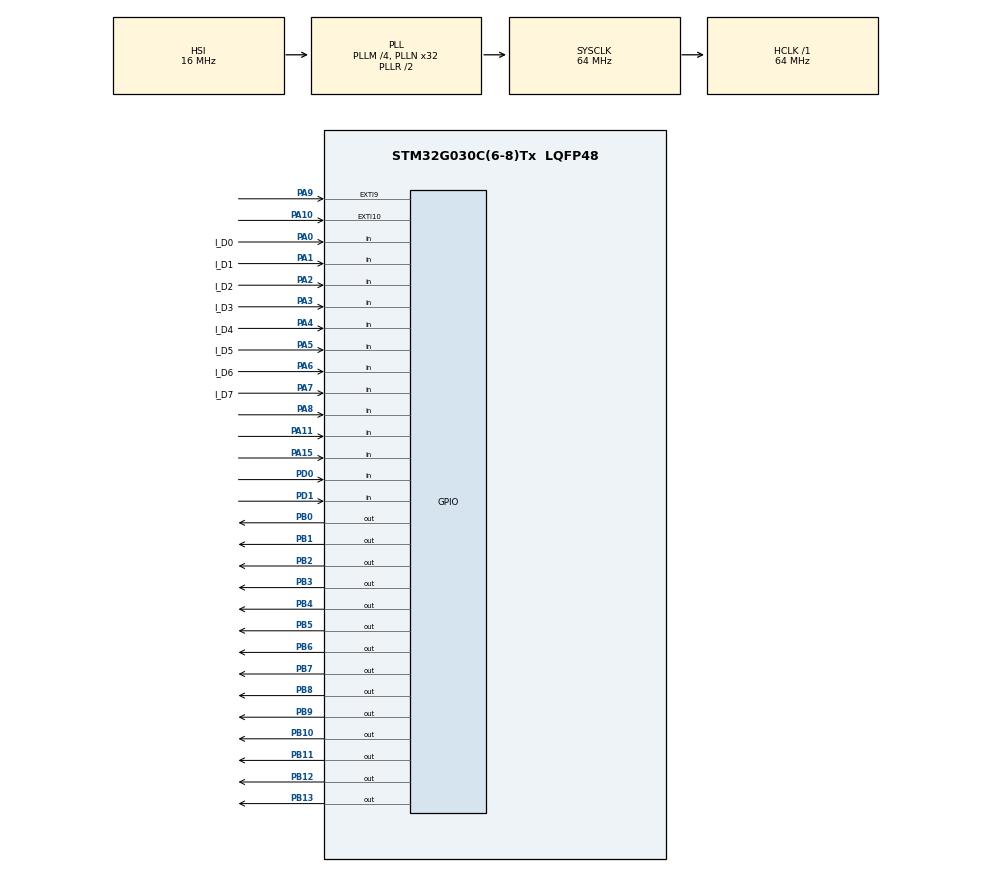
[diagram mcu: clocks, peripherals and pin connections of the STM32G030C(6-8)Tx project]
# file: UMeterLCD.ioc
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Mcu.Family=STM32G0
Mcu.Name=STM32G030C(6-8)Tx
Mcu.Package=LQFP48
NVIC.EXTI4_15_IRQn=true\:0\:0\:false\:false\:true\:true\:true\:true
PA0.GPIO_Label=I_D0
PA0.GPIO_PuPd=GPIO_NOPULL
PA0.Signal=GPIO_Input
PA1.GPIO_Label=I_D1
PA1.GPIO_PuPd=GPIO_NOPULL
PA1.Signal=GPIO_Input
PA10.GPIO_ModeDefaultEXTI=GPIO_MODE_IT_RISING
PA10.GPIO_PuPd=GPIO_NOPULL
PA10.Signal=GPXTI10
PA11\ [PA9].GPIO_PuPd=GPIO_NOPULL
PA11\ [PA9].Signal=GPIO_Input
PA15.GPIO_PuPd=GPIO_PULLUP
PA15.Signal=GPIO_Input
PA2.GPIO_Label=I_D2
PA2.GPIO_PuPd=GPIO_NOPULL
PA2.Signal=GPIO_Input
PA3.GPIO_Label=I_D3
PA3.GPIO_PuPd=GPIO_NOPULL
PA3.Signal=GPIO_Input
PA4.GPIO_Label=I_D4
PA4.GPIO_PuPd=GPIO_NOPULL
PA4.Signal=GPIO_Input
PA5.GPIO_Label=I_D5
PA5.GPIO_PuPd=GPIO_NOPULL
PA5.Signal=GPIO_Input
PA6.GPIO_Label=I_D6
PA6.GPIO_PuPd=GPIO_NOPULL
PA6.Signal=GPIO_Input
PA7.GPIO_Label=I_D7
PA7.GPIO_PuPd=GPIO_NOPULL
PA7.Signal=GPIO_Input
PA8.Signal=GPIO_Input
PA9.GPIO_ModeDefaultEXTI=GPIO_MODE_IT_FALLING
PA9.Signal=GPXTI9
PB0.GPIO_ModeDefaultOutputPP=GPIO_MODE_OUTPUT_PP
PB0.GPIO_PuPd=GPIO_NOPULL
PB0.GPIO_Speed=GPIO_SPEED_FREQ_VERY_HIGH
PB0.Signal=GPIO_Output
PB1.GPIO_PuPd=GPIO_NOPULL
PB1.GPIO_Speed=GPIO_SPEED_FREQ_VERY_HIGH
PB1.Signal=GPIO_Output
PB10.GPIO_PuPd=GPIO_NOPULL
PB10.GPIO_Speed=GPIO_SPEED_FREQ_VERY_HIGH
PB10.PinState=GPIO_PIN_SET
PB10.Signal=GPIO_Output
PB11.GPIO_PuPd=GPIO_NOPULL
PB11.GPIO_Speed=GPIO_SPEED_FREQ_VERY_HIGH
PB11.Signal=GPIO_Output
PB12.GPIO_PuPd=GPIO_NOPULL
PB12.GPIO_Speed=GPIO_SPEED_FREQ_VERY_HIGH
PB12.Signal=GPIO_Output
PB13.PinState=GPIO_PIN_SET
PB13.Signal=GPIO_Output
PB2.GPIO_PuPd=GPIO_NOPULL
PB2.GPIO_Speed=GPIO_SPEED_FREQ_VERY_HIGH
PB2.Signal=GPIO_Output
PB3.GPIO_PuPd=GPIO_NOPULL
PB3.GPIO_Speed=GPIO_SPEED_FREQ_VERY_HIGH
PB3.Signal=GPIO_Output
PB4.GPIO_PuPd=GPIO_NOPULL
PB4.GPIO_Speed=GPIO_SPEED_FREQ_VERY_HIGH
PB4.Signal=GPIO_Output
PB5.GPIO_PuPd=GPIO_NOPULL
PB5.GPIO_Speed=GPIO_SPEED_FREQ_VERY_HIGH
PB5.Signal=GPIO_Output
PB6.GPIO_PuPd=GPIO_NOPULL
PB6.GPIO_Speed=GPIO_SPEED_FREQ_VERY_HIGH
PB6.Signal=GPIO_Output
PB7.GPIO_PuPd=GPIO_NOPULL
PB7.GPIO_Speed=GPIO_SPEED_FREQ_VERY_HIGH
PB7.Signal=GPIO_Output
PB8.GPIO_PuPd=GPIO_NOPULL
PB8.GPIO_Speed=GPIO_SPEED_FREQ_VERY_HIGH
PB8.PinState=GPIO_PIN_SET
PB8.Signal=GPIO_Output
PB9.GPIO_PuPd=GPIO_NOPULL
PB9.GPIO_Speed=GPIO_SPEED_FREQ_VERY_HIGH
PB9.Signal=GPIO_Output
PD0.GPIO_PuPd=GPIO_PULLUP
PD0.Signal=GPIO_Input
PD1.GPIO_PuPd=GPIO_PULLUP
PD1.Signal=GPIO_Input
ProjectManager.HeapSize=0x200
ProjectManager.StackSize=0x400
ProjectManager.TargetToolchain=STM32CubeIDE
RCC.ADCFreq_Value=64000000
RCC.AHBFreq_Value=64000000
RCC.CortexFreq_Value=64000000
RCC.EXTERNAL_CLOCK_VALUE=12288000
RCC.HCLKFreq_Value=64000000
RCC.HSE_VALUE=8000000
RCC.HSI_VALUE=16000000
RCC.LSE_VALUE=32768
RCC.PLLM=RCC_PLLM_DIV4
RCC.PLLN=32
RCC.SYSCLKFreq_VALUE=64000000
RCC.SYSCLKSource=RCC_SYSCLKSOURCE_PLLCLK
RCC.VCOOutputFreq_Value=128000000
TIM1.AutoReloadPreload=TIM_AUTORELOAD_PRELOAD_ENABLE
TIM1.Period=1024
TIM1.Prescaler=0
VP_TIM1_VS_ClockSourceINT.Mode=Internal
board=custom

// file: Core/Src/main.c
/* USER CODE BEGIN Header */
/**
  ******************************************************************************
  * @file           main.c
  * @brief          Main program body for LCD interface controller
  * @details        Controls an LCD display via GPIO and interrupt-driven
  *                 communication protocol
  *
  * @date    July 21, 2025
  * @author  Stuart
  ******************************************************************************
  * @attention
  *
  * Copyright (c) 2022 STMicroelectronics.
  * All rights reserved.
  *
  * This software is licensed under terms that can be found in the LICENSE file
  * in the root directory of this software component.
  * If no LICENSE file comes with this software, it is provided AS-IS.
  *
  ******************************************************************************
  */
/* USER CODE END Header */
#include "main.h"

TIM_HandleTypeDef htim1;

/* USER CODE BEGIN PV */
/*
 * Timer used for PWM generation and timing control
 * Currently unused but kept for potential future features
 */
//uint16_t fade_counter = 1024;

/* USER CODE END PV */

void SystemClock_Config(void);
static void MX_GPIO_Init(void);
static void MX_TIM1_Init(void);

int main(void)
{
  /* USER CODE BEGIN 1 */
  /* Initial setup before system configuration */

  /* Disabled code preserved for reference:
  //while(1);
  //TIM1->CCR1 = 1024;
  */

  /* USER CODE END 1 */

  /* MCU Configuration--------------------------------------------------------*/

  /* Reset of all peripherals, Initializes the Flash interface and the Systick. */
  HAL_Init();

  /* Configure the system clock */
  SystemClock_Config();

  /* Initialize all configured peripherals */
  MX_GPIO_Init();
  MX_TIM1_Init();
  /* USER CODE BEGIN 2 */

  /* Initialize the LCD display
   * This function is defined elsewhere and configures the display
   * for proper operation with the interrupt handler
   */
  HAL_Delay(250);
  displayInit();

  /* Disabled PWM functionality preserved for reference:
  //HAL_TIMEx_PWMN_Start(&htim1, TIM_CHANNEL_1);
  //HAL_Delay(1000);
  //GPIOB->ODR &= ~(0b0000000100000000);
  //GPIOB->ODR |= 0b0000010000000000;
  */

  /* USER CODE END 2 */

  /* Infinite loop */
  while (1)
  {

    /* USER CODE BEGIN 3 */

    /* Enter sleep mode to save power
     * The system will wake up when an interrupt occurs
     * All LCD communication is handled by the interrupt handler
     */
    HAL_PWR_EnterSLEEPMode(PWR_MAINREGULATOR_ON, PWR_SLEEPENTRY_WFI);

    /* Disabled PWM fade effect preserved for reference:
    //if(fade_counter > 0)
    //{
    //  fade_counter -= 1;
    //  TIM1->CCR1 = fade_counter;
    //  HAL_Delay(1);
    //}
    */

    /* Debug signal toggle (currently disabled)
    //GPIOB->ODR |= (1<<13);
    */
  }
  /* USER CODE END 3 */
}

void SystemClock_Config(void)
{
  RCC_OscInitTypeDef RCC_OscInitStruct = {0};
  RCC_ClkInitTypeDef RCC_ClkInitStruct = {0};

  /** Configure the main internal regulator output voltage
  */
  HAL_PWREx_ControlVoltageScaling(PWR_REGULATOR_VOLTAGE_SCALE1);

  /** Initializes the RCC Oscillators according to the specified parameters
  * in the RCC_OscInitTypeDef structure.
  */
  RCC_OscInitStruct.OscillatorType = RCC_OSCILLATORTYPE_HSI;
  RCC_OscInitStruct.HSIState = RCC_HSI_ON;
  RCC_OscInitStruct.HSIDiv = RCC_HSI_DIV1;
  RCC_OscInitStruct.HSICalibrationValue = RCC_HSICALIBRATION_DEFAULT;
  RCC_OscInitStruct.PLL.PLLState = RCC_PLL_ON;
  RCC_OscInitStruct.PLL.PLLSource = RCC_PLLSOURCE_HSI;
  RCC_OscInitStruct.PLL.PLLM = RCC_PLLM_DIV4;
  RCC_OscInitStruct.PLL.PLLN = 32;
  RCC_OscInitStruct.PLL.PLLP = RCC_PLLP_DIV2;
  RCC_OscInitStruct.PLL.PLLR = RCC_PLLR_DIV2;
  if (HAL_RCC_OscConfig(&RCC_OscInitStruct) != HAL_OK)
  {
    Error_Handler();
  }

  /** Initializes the CPU, AHB and APB buses clocks
  */
  RCC_ClkInitStruct.ClockType = RCC_CLOCKTYPE_HCLK|RCC_CLOCKTYPE_SYSCLK
                              |RCC_CLOCKTYPE_PCLK1;
  RCC_ClkInitStruct.SYSCLKSource = RCC_SYSCLKSOURCE_PLLCLK;
  RCC_ClkInitStruct.AHBCLKDivider = RCC_SYSCLK_DIV1;
  RCC_ClkInitStruct.APB1CLKDivider = RCC_HCLK_DIV1;

  if (HAL_RCC_ClockConfig(&RCC_ClkInitStruct, FLASH_LATENCY_2) != HAL_OK)
  {
    Error_Handler();
  }
}

static void MX_TIM1_Init(void)
{

  TIM_ClockConfigTypeDef sClockSourceConfig = {0};
  TIM_MasterConfigTypeDef sMasterConfig = {0};

  htim1.Instance = TIM1;
  htim1.Init.Prescaler = 0;
  htim1.Init.CounterMode = TIM_COUNTERMODE_UP;
  htim1.Init.Period = 1024;
  htim1.Init.ClockDivision = TIM_CLOCKDIVISION_DIV1;
  htim1.Init.RepetitionCounter = 0;
  htim1.Init.AutoReloadPreload = TIM_AUTORELOAD_PRELOAD_ENABLE;
  if (HAL_TIM_Base_Init(&htim1) != HAL_OK)
  {
    Error_Handler();
  }
  sClockSourceConfig.ClockSource = TIM_CLOCKSOURCE_INTERNAL;
  if (HAL_TIM_ConfigClockSource(&htim1, &sClockSourceConfig) != HAL_OK)
  {
    Error_Handler();
  }
  sMasterConfig.MasterOutputTrigger = TIM_TRGO_RESET;
  sMasterConfig.MasterOutputTrigger2 = TIM_TRGO2_RESET;
  sMasterConfig.MasterSlaveMode = TIM_MASTERSLAVEMODE_DISABLE;
  if (HAL_TIMEx_MasterConfigSynchronization(&htim1, &sMasterConfig) != HAL_OK)
  {
    Error_Handler();
  }
}

static void MX_GPIO_Init(void)
{
  GPIO_InitTypeDef GPIO_InitStruct = {0};

  /* GPIO Ports Clock Enable */
  __HAL_RCC_GPIOA_CLK_ENABLE();  /* Port A for input data and control signals */
  __HAL_RCC_GPIOB_CLK_ENABLE();  /* Port B for output data and control signals */
  __HAL_RCC_GPIOD_CLK_ENABLE();  /* Port D for additional inputs */

  /* Configure GPIO output levels */
  /* Data pins and most control pins default to LOW */
  HAL_GPIO_WritePin(GPIOB, GPIO_PIN_0|GPIO_PIN_1|GPIO_PIN_2|GPIO_PIN_11
                          |GPIO_PIN_12|GPIO_PIN_3|GPIO_PIN_4|GPIO_PIN_5
                          |GPIO_PIN_6|GPIO_PIN_7|GPIO_PIN_9, GPIO_PIN_RESET);

  /* Control pins that need to start HIGH */
  HAL_GPIO_WritePin(GPIOB, GPIO_PIN_10|GPIO_PIN_13|GPIO_PIN_8, GPIO_PIN_SET);

  /* Configure input pins for LCD data bus (PA0-PA7) and control signals */
  GPIO_InitStruct.Pin = I_D0_Pin|I_D1_Pin|I_D2_Pin|I_D3_Pin
                          |I_D4_Pin|I_D5_Pin|I_D6_Pin|I_D7_Pin
                          |GPIO_PIN_8|GPIO_PIN_11;
  GPIO_InitStruct.Mode = GPIO_MODE_INPUT;
  GPIO_InitStruct.Pull = GPIO_NOPULL;
  HAL_GPIO_Init(GPIOA, &GPIO_InitStruct);

  /* Configure output pins for LCD control and data signals
   * Using high-speed configuration for timing-critical signals
   */
  GPIO_InitStruct.Pin = GPIO_PIN_0|GPIO_PIN_1|GPIO_PIN_2|GPIO_PIN_10
                          |GPIO_PIN_11|GPIO_PIN_12|GPIO_PIN_3|GPIO_PIN_4
                          |GPIO_PIN_5|GPIO_PIN_6|GPIO_PIN_7|GPIO_PIN_8
                          |GPIO_PIN_9;
  GPIO_InitStruct.Mode = GPIO_MODE_OUTPUT_PP;
  GPIO_InitStruct.Pull = GPIO_NOPULL;
  GPIO_InitStruct.Speed = GPIO_SPEED_FREQ_VERY_HIGH;
  HAL_GPIO_Init(GPIOB, &GPIO_InitStruct);

  /* Configure PB13 pin with lower speed (used for status/debug) */
  GPIO_InitStruct.Pin = GPIO_PIN_13;
  GPIO_InitStruct.Mode = GPIO_MODE_OUTPUT_PP;
  GPIO_InitStruct.Pull = GPIO_NOPULL;
  GPIO_InitStruct.Speed = GPIO_SPEED_FREQ_LOW;
  HAL_GPIO_Init(GPIOB, &GPIO_InitStruct);

  /* Configure PA9 as input (ERD signal) */
  GPIO_InitStruct.Pin = GPIO_PIN_9;
  GPIO_InitStruct.Mode = GPIO_MODE_INPUT;  /* No interrupt, just input */
  GPIO_InitStruct.Pull = GPIO_PULLUP;
  HAL_GPIO_Init(GPIOA, &GPIO_InitStruct);

  /* Configure PA10 as interrupt input (Strobe signal) */
  GPIO_InitStruct.Pin = GPIO_PIN_10;
  GPIO_InitStruct.Mode = GPIO_MODE_IT_RISING;  /* Interrupt on rising edge */
  GPIO_InitStruct.Pull = GPIO_PULLUP;
  HAL_GPIO_Init(GPIOA, &GPIO_InitStruct);

  /* Configure additional input pins with pull-ups */
  GPIO_InitStruct.Pin = GPIO_PIN_15;
  GPIO_InitStruct.Mode = GPIO_MODE_INPUT;
  GPIO_InitStruct.Pull = GPIO_PULLUP;
  HAL_GPIO_Init(GPIOA, &GPIO_InitStruct);

  GPIO_InitStruct.Pin = GPIO_PIN_0|GPIO_PIN_1;
  GPIO_InitStruct.Mode = GPIO_MODE_INPUT;
  GPIO_InitStruct.Pull = GPIO_PULLUP;
  HAL_GPIO_Init(GPIOD, &GPIO_InitStruct);

  /* Configure the EXTI interrupt controller for PA10 */
  HAL_NVIC_SetPriority(EXTI4_15_IRQn, 0, 0);
  HAL_NVIC_EnableIRQ(EXTI4_15_IRQn);
}

void Error_Handler(void)
{
  /* USER CODE BEGIN Error_Handler_Debug */
  /* User can add his own implementation to report the HAL error return state */

  /* Original error handler code (disabled but preserved)
  //__disable_irq();
  //while (1)
  //{
  //}
  */

  /* Current implementation continues execution even after errors */
  /* USER CODE END Error_Handler_Debug */
}
